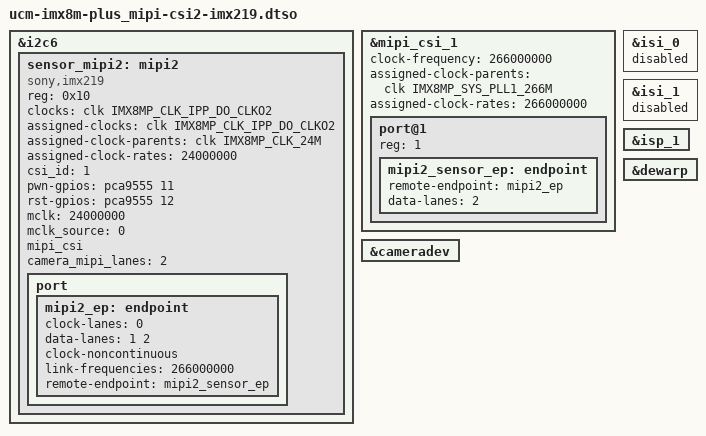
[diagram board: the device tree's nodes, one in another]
#include "overlay.h"

&i2c6 {
	#address-cells = <1>;
	#size-cells = <0>;
	status = "okay";

	sensor_mipi2: mipi2 {
		compatible = "sony,imx219";
		reg = <0x10>;
		clocks = <&clk IMX8MP_CLK_IPP_DO_CLKO2>;
		clock-names = "xclk";
		assigned-clocks = <&clk IMX8MP_CLK_IPP_DO_CLKO2>;
		assigned-clock-parents = <&clk IMX8MP_CLK_24M>;
		assigned-clock-rates = <24000000>;
		csi_id = <1>;
		pwn-gpios = <&pca9555 11 GPIO_ACTIVE_HIGH>;
		rst-gpios = <&pca9555 12 GPIO_ACTIVE_HIGH>;
		mclk = <24000000>;
		mclk_source = <0>;
		mipi_csi;
		camera_mipi_lanes = <2>;
		status = "okay";

		port {
			mipi2_ep: endpoint {
				clock-lanes = <0>;
				data-lanes = <1 2>;
				clock-noncontinuous;
				link-frequencies = /bits/ 64 <266000000>;
				remote-endpoint = <&mipi2_sensor_ep>;
			};
		};
	};
};

&mipi_csi_1 {
	status = "okay";
	clock-frequency = <266000000>;
	assigned-clock-parents = <&clk IMX8MP_SYS_PLL1_266M>;
	assigned-clock-rates = <266000000>;
	#address-cells = <1>;
	#size-cells = <0>;
	port@1 {
		reg = <1>;
		mipi2_sensor_ep: endpoint {
			remote-endpoint = <&mipi2_ep>;
			data-lanes = <2>;
		};
	};
};

&cameradev {
	status = "okay";
};

&isi_0 {
	status = "disabled";

};

&isi_1 {
	status = "disabled";

};

&isp_1 {
	status = "okay";
};

&dewarp {
	status = "okay";
};

